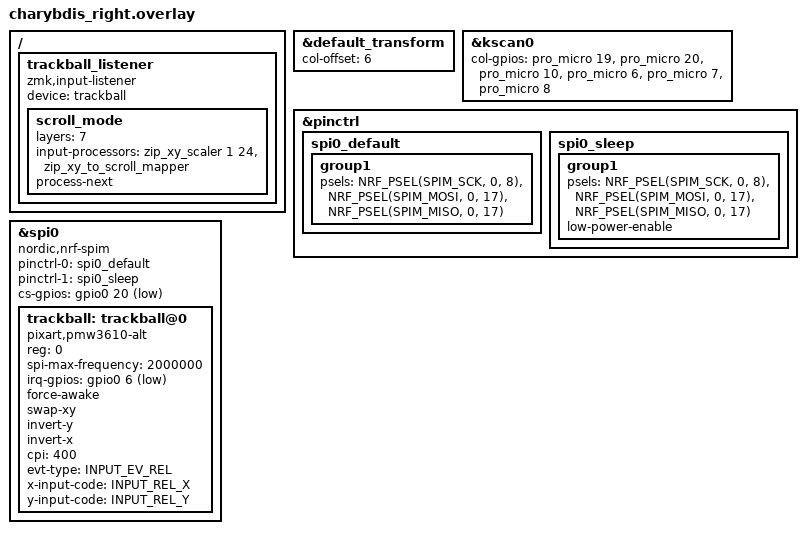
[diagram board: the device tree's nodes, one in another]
/*
 * Copyright (c) 2020 ZMK Contributors
 *
 * SPDX-License-Identifier: MIT
 */
 
#include "charybdis.dtsi"
#include <input/processors.dtsi>

&default_transform {
	col-offset = <6>;
};



&kscan0 {
	col-gpios
		= <&pro_micro 19 (GPIO_ACTIVE_HIGH | GPIO_PULL_DOWN)>
		, <&pro_micro 20 (GPIO_ACTIVE_HIGH | GPIO_PULL_DOWN)>
		, <&pro_micro 10 (GPIO_ACTIVE_HIGH | GPIO_PULL_DOWN)>
		, <&pro_micro 6 (GPIO_ACTIVE_HIGH | GPIO_PULL_DOWN)>
		, <&pro_micro 7 (GPIO_ACTIVE_HIGH | GPIO_PULL_DOWN)>
		, <&pro_micro 8 (GPIO_ACTIVE_HIGH | GPIO_PULL_DOWN)>
		;
};

&pinctrl {
    spi0_default: spi0_default {
        group1 {
            psels = <NRF_PSEL(SPIM_SCK, 0, 8)>,
                <NRF_PSEL(SPIM_MOSI, 0, 17)>,
                <NRF_PSEL(SPIM_MISO, 0, 17)>;
        };
    };

    spi0_sleep: spi0_sleep {
        group1 {
            psels = <NRF_PSEL(SPIM_SCK, 0, 8)>,
                <NRF_PSEL(SPIM_MOSI, 0, 17)>,
                <NRF_PSEL(SPIM_MISO, 0, 17)>;
            low-power-enable;
        };
    };
};

/* Configure the sensor on the SPI bus */
&spi0 {
    status = "okay";
    compatible = "nordic,nrf-spim";
    pinctrl-0 = <&spi0_default>;
    pinctrl-1 = <&spi0_sleep>;
    pinctrl-names = "default", "sleep";
    cs-gpios = <&gpio0 20 GPIO_ACTIVE_LOW>; /* CHECK YOUR PIN: This might be different for your wiring! */

    trackball: trackball@0 {
        status = "okay";
        compatible = "pixart,pmw3610-alt"; /* Use the 'alt' driver */
        reg = <0>;
        spi-max-frequency = <2000000>;
        irq-gpios = <&gpio0 6 (GPIO_ACTIVE_LOW | GPIO_PULL_UP)>; /* CHECK YOUR PIN */
        
        /* EFFICIENCY SETTINGS */
        /* Forces 4ms polling (250Hz) for smoother tracking */
        force-awake;
        /* force-awake-4ms-mode;  */
        swap-xy;
        invert-y;
        invert-x;
        /* Adjust CPI (DPI) to preference */
        cpi = <400>;
        /* scale-multiplier = <1>; */
        /* scale-divisor = <1>; */
        
        /* Orientation mappings (adjust as needed for your specific rotation) */
        evt-type = <INPUT_EV_REL>;
        x-input-code = <INPUT_REL_X>;
        y-input-code = <INPUT_REL_Y>;
    };
};

/* Add the input listener at the root level */
/ {
    trackball_listener {
        compatible = "zmk,input-listener";
        device = <&trackball>;

        scroll_mode {
            layers = <7>;
            input-processors = <&zip_xy_scaler 1 24>,
                               <&zip_xy_to_scroll_mapper>;
            process-next;
        };
        /* Optional: Scale output (X, Y). Increase for speed, decrease for precision */
        
    };
};

